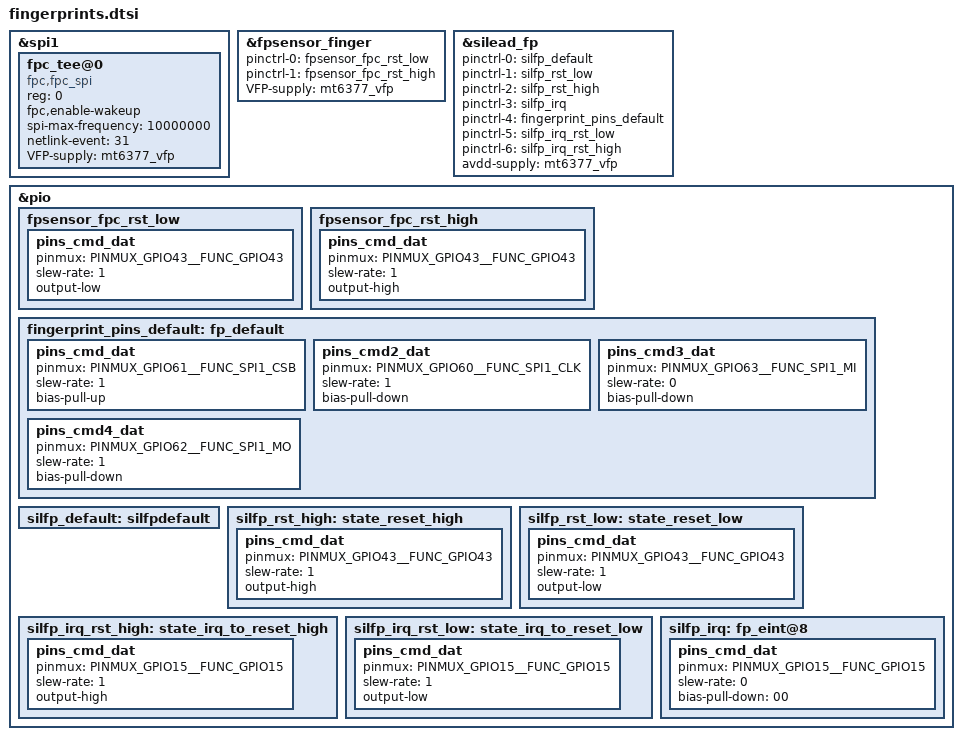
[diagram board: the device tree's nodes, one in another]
&spi1 {
	#address-cells = <1>;
	#size-cells = <0>;
	fpc_tee@0 {
		compatible = "fpc,fpc_spi";
		reg = <0>;
		fpc,enable-wakeup;
		spi-max-frequency = <10000000>;
		netlink-event = <31>;
                VFP-supply = <&mt6377_vfp>;
		status = "okay";
	};
};
&fpsensor_finger {
	pinctrl-names = "fpsensor_fpc_rst_low", "fpsensor_fpc_rst_high";
	pinctrl-0 = <&fpsensor_fpc_rst_low>;
	pinctrl-1 = <&fpsensor_fpc_rst_high>;
	VFP-supply = <&mt6377_vfp>;
	status = "okay";
};

&silead_fp {
	pinctrl-names = "default", "rst-low", "rst-high" ,
	                "irq-init", "spi-default", "irq_rst-low", "irq_rst-high";
	pinctrl-0 = <&silfp_default>;
	pinctrl-1 = <&silfp_rst_low>;
	pinctrl-2 = <&silfp_rst_high>;
	pinctrl-3 = <&silfp_irq>;
	pinctrl-4 = <&fingerprint_pins_default>;
	pinctrl-5 = <&silfp_irq_rst_low>;
	pinctrl-6 = <&silfp_irq_rst_high>;
	avdd-supply = <&mt6377_vfp>;
	status = "okay";
};

&pio {
	fpsensor_fpc_rst_low: fpsensor_fpc_rst_low {
		pins_cmd_dat {
			pinmux = <PINMUX_GPIO43__FUNC_GPIO43>;
			slew-rate = <1>;
			output-low;
		};
	};
	fpsensor_fpc_rst_high: fpsensor_fpc_rst_high {
		pins_cmd_dat {
			pinmux = <PINMUX_GPIO43__FUNC_GPIO43>;
			slew-rate = <1>;
			output-high;
		};
	};

};

&pio {
	fingerprint_pins_default: fp_default {
		pins_cmd_dat {
			pinmux = <PINMUX_GPIO61__FUNC_SPI1_CSB>;
			slew-rate = <1>;
			bias-pull-up;
		};

		pins_cmd2_dat {
			pinmux = <PINMUX_GPIO60__FUNC_SPI1_CLK>;
			slew-rate = <1>;
			bias-pull-down;
		};

		pins_cmd3_dat {
			pinmux = <PINMUX_GPIO63__FUNC_SPI1_MI>;
			slew-rate = <0>;
			bias-pull-down;
		};

		pins_cmd4_dat {
			pinmux = <PINMUX_GPIO62__FUNC_SPI1_MO>;
			slew-rate = <1>;
			bias-pull-down;
		};
	};
};

&pio {
	silfp_default: silfpdefault {
	};

	silfp_rst_high: state_reset_high {
		pins_cmd_dat {
			pinmux = <PINMUX_GPIO43__FUNC_GPIO43>;
			slew-rate = <1>;
			output-high;
		};
	};

	silfp_rst_low: state_reset_low {
		pins_cmd_dat {
			pinmux = <PINMUX_GPIO43__FUNC_GPIO43>;
			slew-rate = <1>;
			output-low;
		};
	};

	silfp_irq_rst_high: state_irq_to_reset_high {
		pins_cmd_dat {
			pinmux = <PINMUX_GPIO15__FUNC_GPIO15>;
			slew-rate = <1>;
			output-high;
		};
	};

	silfp_irq_rst_low: state_irq_to_reset_low {
		pins_cmd_dat {
			pinmux = <PINMUX_GPIO15__FUNC_GPIO15>;
			slew-rate = <1>;
			output-low;
		};
	};

	silfp_irq: fp_eint@8 {
		pins_cmd_dat {
			pinmux = <PINMUX_GPIO15__FUNC_GPIO15>;
			slew-rate = <0>;
			bias-pull-down = <00>;
		};
	};
};
